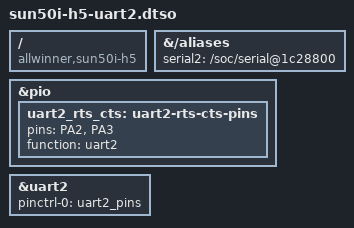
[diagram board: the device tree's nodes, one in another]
/dts-v1/;
/plugin/;

/ {
	compatible = "allwinner,sun50i-h5";

	fragment@0 {
		target-path = "/aliases";
		__overlay__ {
			serial2 = "/soc/serial@1c28800";
		};
	};

	fragment@1 {
		target = <&pio>;
		__overlay__ {
			uart2_rts_cts: uart2-rts-cts-pins {
				pins = "PA2", "PA3";
				function = "uart2";
			};
		};
	};

	fragment@2 {
		target = <&uart2>;
		 __overlay__ {
			pinctrl-names = "default";
			pinctrl-0 = <&uart2_pins>;
			status = "okay";
		};
	};
};
